# ATmega169PA register map
Vendor: Atmel; File version: 1.0
CPU: other r0p0, little endian, no MPU, no FPU, 4 interrupt priority bits
Registers are 8-bit, read-write, reset 0x0 unless marked. A register's access mark holds for its fields unless they carry their own. Offsets are from the block's base; [hi:lo] are bit positions; {n}, {i} and the like mark numbered series.

## BOOT_LOAD — Bootloader
Base 0x00800057
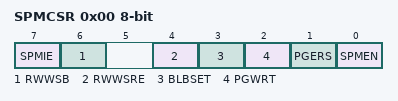
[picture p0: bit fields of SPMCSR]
0x00 SPMCSR — Store Program Memory Control Register
  [7] SPMIE — SPM Interrupt Enable
  [6] RWWSB — Read While Write Section Busy
  [4] RWWSRE — Read While Write section read enable
  [3] BLBSET — Boot Lock Bit Set
  [2] PGWRT — Page Write
  [1] PGERS — Page Erase
  [0] SPMEN — Store Program Memory Enable

## CPU — CPU Registers
Base 0x0080003E
0x00 GPIOR0 — General Purpose IO Register 0
  [7:0] GPIOR0 — General Purpose Bits
0x0C GPIOR1 — General Purpose IO Register 1
  [7:0] GPIOR1 — General Purpose Bits
0x0D GPIOR2 — General Purpose IO Register 2
  [7:0] GPIOR2 — General Purpose Bits
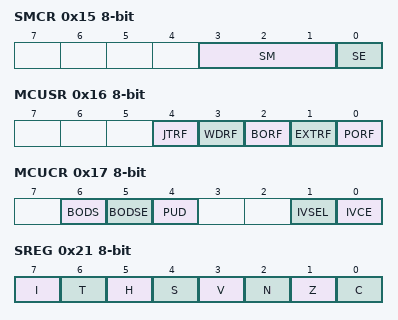
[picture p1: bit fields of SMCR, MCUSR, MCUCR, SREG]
0x15 SMCR — Sleep Mode Control Register
  [3:1] SM — Sleep Mode Select bits
    0=IDLE; 1=ADC (ADC Noise Reduction (If Available)); 2=PDOWN (Power Down); 3=PSAVE (Power Save); 6=STDBY (Standby)
  [0] SE — Sleep Enable
0x16 MCUSR — MCU Status Register
  [4] JTRF — JTAG Reset Flag
  [3] WDRF — Watchdog Reset Flag
  [2] BORF — Brown-out Reset Flag
  [1] EXTRF — External Reset Flag
  [0] PORF — Power-on reset flag
0x17 MCUCR — MCU Control Register
  [6] BODS — BOD Sleep
  [5] BODSE — BOD Sleep Enable
  [4] PUD — Pull-up disable
  [1] IVSEL — Interrupt Vector Select
  [0] IVCE — Interrupt Vector Change Enable
0x1F SP 16-bit (reset mask 0xFF) — Stack Pointer
0x21 SREG — Status Register
  [7] I — Global Interrupt Enable
  [6] T — Bit Copy Storage
  [5] H — Half Carry Flag
  [4] S — Sign Bit
  [3] V — Two's Complement Overflow Flag
  [2] N — Negative Flag
  [1] Z — Zero Flag
  [0] C — Carry Flag
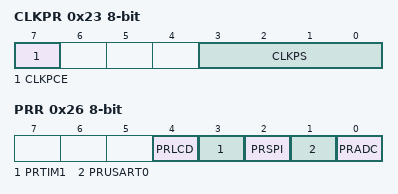
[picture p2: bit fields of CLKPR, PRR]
0x23 CLKPR — Clock Prescale Register
  [7] CLKPCE — Clock Prescaler Change Enable
  [3:0] CLKPS — Clock Prescaler Select Bits
    0=1; 1=2; 2=4; 3=8; 4=16; 5=32; 6=64; 7=128; 8=256
0x26 PRR — Power Reduction Register
  [4] PRLCD — Power Reduction LCD
  [3] PRTIM1 — Power Reduction Timer/Counter1
  [2] PRSPI — Power Reduction Serial Peripheral Interface
  [1] PRUSART0 — Power Reduction USART
  [0] PRADC — Power Reduction ADC
0x28 OSCCAL — Oscillator Calibration Value
  [7:0] OSCCAL — Oscillator Calibration

## EEPROM
Base 0x0080003F
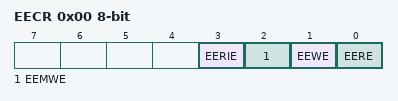
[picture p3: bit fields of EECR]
0x00 EECR — EEPROM Control Register
  [3] EERIE — EEPROM Ready Interrupt Enable
  [2] EEMWE — EEPROM Master Write Enable
  [1] EEWE — EEPROM Write Enable
  [0] EERE — EEPROM Read Enable
0x01 EEDR — EEPROM Data Register
  [7:0] EEDR — EEPROM Data Bits
0x02 EEAR 16-bit (reset mask 0xFF) — EEPROM Address Register Bytes
  [8:0] EEAR — EEPROM Address Bits

## EXINT — External Interrupts
Base 0x0080003C
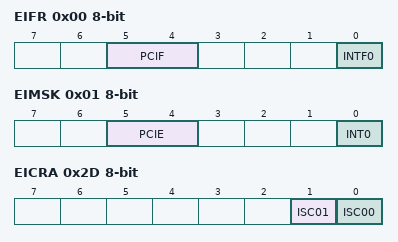
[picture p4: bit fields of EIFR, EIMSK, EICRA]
0x00 EIFR — External Interrupt Flag Register (read-only for debugger)
  [5:4] PCIF — Pin Change Interrupt Flags
  [0] INTF0 — External Interrupt Flag 0
0x01 EIMSK — External Interrupt Mask Register
  [5:4] PCIE — Pin Change Interrupt Enables
  [0] INT0 — External Interrupt Request 0 Enable
0x2D EICRA — External Interrupt Control Register
  [1] ISC01 — External Interrupt Sense Control 0 Bit 1
  [0] ISC00 — External Interrupt Sense Control 0 Bit 0
    0=LOW_LEVEL_OF_INTX; 1=ANY_LOGICAL_CHANGE_OF_INTX
0x2F PCMSK0 — Pin Change Mask Register 0
  [7:0] PCINT — Pin Change Enable Masks
0x30 PCMSK1 — Pin Change Mask Register 1
  [7:0] PCINT — Pin Change Enable Masks

## JTAG — JTAG Interface
Base 0x00800051
0x00 OCDR — On-Chip Debug Related Register in I/O Memory (write-only for debugger)
0x03 MCUSR — MCU Status Register (read-only for debugger)
  [4] JTRF — JTAG Reset Flag
0x04 MCUCR — MCU Control Register
  [7] JTD — JTAG Interface Disable

## LCD — Liquid Crystal Display
Base 0x008000E4
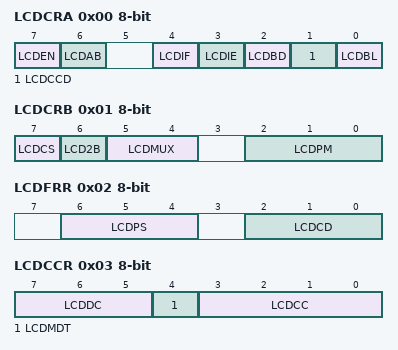
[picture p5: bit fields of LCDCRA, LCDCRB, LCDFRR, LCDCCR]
0x00 LCDCRA — LCD Control Register A (read-only for debugger)
  [7] LCDEN — LCD Enable
  [6] LCDAB — LCD A or B waveform
  [4] LCDIF — LCD Interrupt Flag
  [3] LCDIE — LCD Interrupt Enable
  [2] LCDBD — LCD Buffer Disable
  [1] LCDCCD — LCD Contrast Control Disable
  [0] LCDBL — LCD Blanking
0x01 LCDCRB — LCD Control and Status Register B
  [7] LCDCS — LCD CLock Select
  [6] LCD2B — LCD 1/2 Bias Select
  [5:4] LCDMUX — LCD Mux Selects
  [2:0] LCDPM — LCD Port Masks
    0=SEG0_12; 1=SEG0_14; 2=SEG0_15; 3=SEG0_18; 4=SEG0_20; 5=SEG0_22; 6=SEG0_23; 7=SEG0_24
0x02 LCDFRR — LCD Frame Rate Register
  [6:4] LCDPS — LCD Prescaler Selects
    0=CLKLCD_16; 1=CLKLCD_64; 2=CLKLCD_128; 3=CLKLCD_256; 4=CLKLCD_512; 5=CLKLCD_1024; 6=CLKLCD_2048; 7=CLKLCD_4096
  [2:0] LCDCD — LCD Clock Dividers
    {v}={v+1} (v=0..7)
0x03 LCDCCR — LCD Contrast Control Register
  [7:5] LCDDC — LCD Display Configuration Bits
    0=300US; 1=70US; 2=150US; 3=450US; 4=575US; 5=850US; 6=1150US; 7=50_PERCENT_OF_LCD_CLOCK (50% of LCD clock)
  [4] LCDMDT — LCD Maximum Drive Time
  [3:0] LCDCC — LCD Contrast Controls
    0=2_60V; 1=2_65V; 2=2_70V; 3=2_75V; 4=2_80V; 5=2_85V; 6=2_90V; 7=2_95V; 8=3_00V; 9=3_05V; 10=3_10V; 11=3_15V; 12=3_20V; 13=3_25V; 14=3_30V; 15=3_35V
{0x8+i} LCDDR{i} (i=0..3) — LCD Data Register {i}
{0x8+i} LCDDR{i} (i=5..8) — LCD Data Register {i}
{0x8+i} LCDDR{i} (i=10..13) — LCD Data Register {i}
{0x8+i} LCDDR{i} (i=15..18) — LCD Data Register {i}
